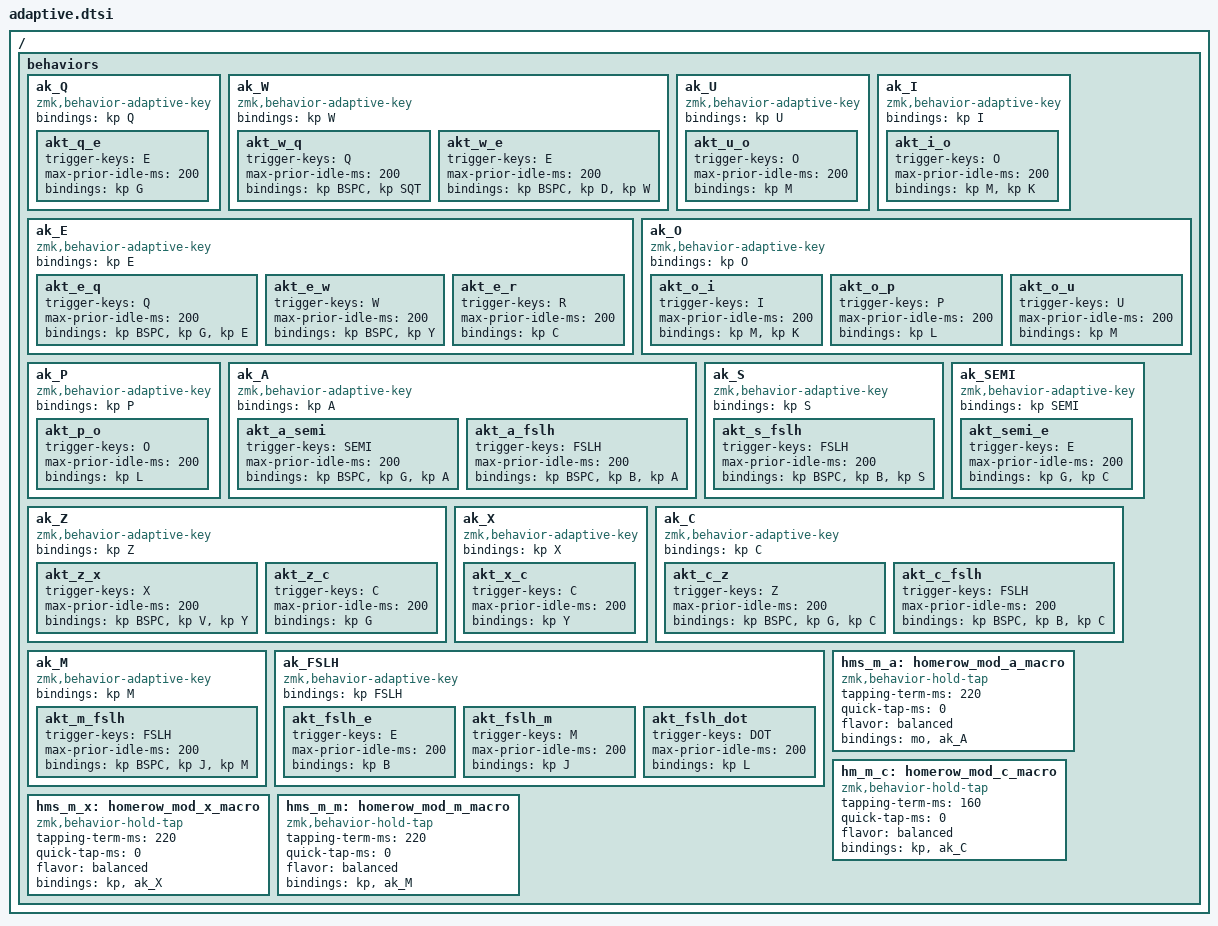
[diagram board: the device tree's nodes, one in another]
/ { behaviors {
	ak_Q: ak_Q {
		compatible = "zmk,behavior-adaptive-key";
		#binding-cells = <0>;
		bindings = <&kp Q>;
		akt_q_e {
			trigger-keys = <E>;
			max-prior-idle-ms = <200>;
			bindings = <&kp G>;
		};
	};

	ak_W: ak_W {
		compatible = "zmk,behavior-adaptive-key";
		#binding-cells = <0>;
		bindings = <&kp W>;
		akt_w_q {
			trigger-keys = <Q>;
			max-prior-idle-ms = <200>;
			bindings = <&kp BSPC &kp SQT>;
		};
		akt_w_e {
			trigger-keys = <E>;
			max-prior-idle-ms = <200>;
			bindings = <&kp BSPC &kp D &kp W>;
		};
	};

	ak_E: ak_E {
		compatible = "zmk,behavior-adaptive-key";
		#binding-cells = <0>;
		bindings = <&kp E>;
		akt_e_q {
			trigger-keys = <Q>;
			max-prior-idle-ms = <200>;
			bindings = <&kp BSPC &kp G &kp E>;
		};
		akt_e_w {
			trigger-keys = <W>;
			max-prior-idle-ms = <200>;
			bindings = <&kp BSPC &kp Y>;
		};
		akt_e_r {
			trigger-keys = <R>;
			max-prior-idle-ms = <200>;
			bindings = <&kp C>;
		};
	};

	ak_U: ak_U {
		compatible = "zmk,behavior-adaptive-key";
		#binding-cells = <0>;
		bindings = <&kp U>;
		akt_u_o {
			trigger-keys = <O>;
			max-prior-idle-ms = <200>;
			bindings = <&kp M>;
		};
	};

	ak_I: ak_I {
		compatible = "zmk,behavior-adaptive-key";
		#binding-cells = <0>;
		bindings = <&kp I>;
		akt_i_o {
			trigger-keys = <O>;
			max-prior-idle-ms = <200>;
			bindings = <&kp M &kp K>;
		};
	};

	ak_O: ak_O {
		compatible = "zmk,behavior-adaptive-key";
		#binding-cells = <0>;
		bindings = <&kp O>;
		akt_o_i {
			trigger-keys = <I>;
			max-prior-idle-ms = <200>;
			bindings = <&kp M &kp K>;
		};
		akt_o_p {
			trigger-keys = <P>;
			max-prior-idle-ms = <200>;
			bindings = <&kp L>;
		};
		akt_o_u {
			trigger-keys = <U>;
			max-prior-idle-ms = <200>;
			bindings = <&kp M>;
		};
	};

	ak_P: ak_P {
		compatible = "zmk,behavior-adaptive-key";
		#binding-cells = <0>;
		bindings = <&kp P>;
		akt_p_o {
			trigger-keys = <O>;
			max-prior-idle-ms = <200>;
			bindings = <&kp L>;
		};
	};

	ak_A: ak_A {
		compatible = "zmk,behavior-adaptive-key";
		#binding-cells = <0>;
		bindings = <&kp A>;
		akt_a_semi {
			trigger-keys = <SEMI>;
			max-prior-idle-ms = <200>;
			bindings = <&kp BSPC &kp G &kp A>;
		};
		akt_a_fslh {
			trigger-keys = <FSLH>;
			max-prior-idle-ms = <200>;
			bindings = <&kp BSPC &kp B &kp A>;
		};
	};

	ak_S: ak_S {
		compatible = "zmk,behavior-adaptive-key";
		#binding-cells = <0>;
		bindings = <&kp S>;
		akt_s_fslh {
			trigger-keys = <FSLH>;
			max-prior-idle-ms = <200>;
			bindings = <&kp BSPC &kp B &kp S>;
		};
	};

	ak_SEMI: ak_SEMI {
		compatible = "zmk,behavior-adaptive-key";
		#binding-cells = <0>;
		bindings = <&kp SEMI>;
		akt_semi_e {
			trigger-keys = <E>;
			max-prior-idle-ms = <200>;
			bindings = <&kp G &kp C>;
		};
	};

	ak_Z: ak_Z {
		compatible = "zmk,behavior-adaptive-key";
		#binding-cells = <0>;
		bindings = <&kp Z>;
		akt_z_x {
			trigger-keys = <X>;
			max-prior-idle-ms = <200>;
			bindings = <&kp BSPC &kp V &kp Y>;
		};
		akt_z_c {
			trigger-keys = <C>;
			max-prior-idle-ms = <200>;
			bindings = <&kp G>;
		};
	};

	ak_X: ak_X {
		compatible = "zmk,behavior-adaptive-key";
		#binding-cells = <0>;
		bindings = <&kp X>;
		akt_x_c {
			trigger-keys = <C>;
			max-prior-idle-ms = <200>;
			bindings = <&kp Y>;
		};
	};

	ak_C: ak_C {
		compatible = "zmk,behavior-adaptive-key";
		#binding-cells = <0>;
		bindings = <&kp C>;
		akt_c_z {
			trigger-keys = <Z>;
			max-prior-idle-ms = <200>;
			bindings = <&kp BSPC &kp G &kp C>;
		};
		akt_c_fslh {
			trigger-keys = <FSLH>;
			max-prior-idle-ms = <200>;
			bindings = <&kp BSPC &kp B &kp C>;
		};
	};

	ak_M: ak_M {
		compatible = "zmk,behavior-adaptive-key";
		#binding-cells = <0>;
		bindings = <&kp M>;
		akt_m_fslh {
			trigger-keys = <FSLH>;
			max-prior-idle-ms = <200>;
			bindings = <&kp BSPC &kp J &kp M>;
		};
	};

	ak_FSLH: ak_FSLH {
		compatible = "zmk,behavior-adaptive-key";
		#binding-cells = <0>;
		bindings = <&kp FSLH>;
		akt_fslh_e {
			trigger-keys = <E>;
			max-prior-idle-ms = <200>;
			bindings = <&kp B>;
		};
		akt_fslh_m {
			trigger-keys = <M>;
			max-prior-idle-ms = <200>;
			bindings = <&kp J>;
		};
		akt_fslh_dot {
			trigger-keys = <DOT>;
			max-prior-idle-ms = <200>;
			bindings = <&kp L>;
		};
	};

	hms_m_a: homerow_mod_a_macro {
		compatible = "zmk,behavior-hold-tap";
		#binding-cells = <2>;
		tapping-term-ms = <220>;
		quick-tap-ms = <0>;
		flavor = "balanced";
		bindings = <&mo>, <&ak_A>;
	};

	hm_m_c: homerow_mod_c_macro {
		compatible = "zmk,behavior-hold-tap";
		#binding-cells = <2>;
		tapping-term-ms = <160>;
		quick-tap-ms = <0>;
		flavor = "balanced";
		bindings = <&kp>, <&ak_C>;
	};

	hms_m_x: homerow_mod_x_macro {
		compatible = "zmk,behavior-hold-tap";
		#binding-cells = <2>;
		tapping-term-ms = <220>;
		quick-tap-ms = <0>;
		flavor = "balanced";
		bindings = <&kp>, <&ak_X>;
	};

	hms_m_m: homerow_mod_m_macro {
		compatible = "zmk,behavior-hold-tap";
		#binding-cells = <2>;
		tapping-term-ms = <220>;
		quick-tap-ms = <0>;
		flavor = "balanced";
		bindings = <&kp>, <&ak_M>;
	};
}; };
